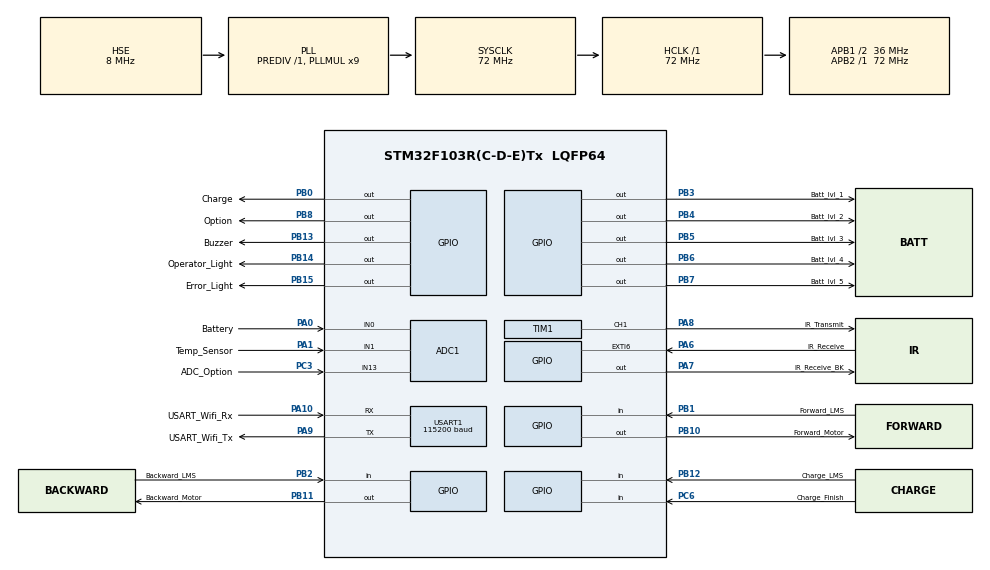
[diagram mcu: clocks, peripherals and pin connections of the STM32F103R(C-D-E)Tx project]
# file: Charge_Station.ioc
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ADC1.Channel-0\#ChannelRegularConversion=ADC_CHANNEL_0
ADC1.Channel-1\#ChannelRegularConversion=ADC_CHANNEL_1
ADC1.Channel-2\#ChannelRegularConversion=ADC_CHANNEL_13
ADC1.ContinuousConvMode=ENABLE
ADC1.DataAlign=ADC_DATAALIGN_RIGHT
ADC1.DiscontinuousConvMode=DISABLE
ADC1.EnableAnalogWatchDog=false
ADC1.EnableRegularConversion=ENABLE
ADC1.ExternalTrigConv=ADC_SOFTWARE_START
ADC1.InjNumberOfConversion=0
ADC1.NbrOfConversion=3
ADC1.NbrOfConversionFlag=1
ADC1.Rank-0\#ChannelRegularConversion=1
ADC1.Rank-1\#ChannelRegularConversion=2
ADC1.Rank-2\#ChannelRegularConversion=3
ADC1.SamplingTime-0\#ChannelRegularConversion=ADC_SAMPLETIME_239CYCLES_5
ADC1.SamplingTime-1\#ChannelRegularConversion=ADC_SAMPLETIME_239CYCLES_5
ADC1.SamplingTime-2\#ChannelRegularConversion=ADC_SAMPLETIME_239CYCLES_5
ADC1.ScanConvMode=ADC_SCAN_ENABLE
ADC1.master=1
Dma.ADC1.1.Direction=DMA_PERIPH_TO_MEMORY
Dma.ADC1.1.Instance=DMA1_Channel1
Dma.ADC1.1.MemDataAlignment=DMA_MDATAALIGN_HALFWORD
Dma.ADC1.1.MemInc=DMA_MINC_ENABLE
Dma.ADC1.1.Mode=DMA_CIRCULAR
Dma.ADC1.1.PeriphDataAlignment=DMA_PDATAALIGN_HALFWORD
Dma.ADC1.1.PeriphInc=DMA_PINC_DISABLE
Dma.ADC1.1.Priority=DMA_PRIORITY_LOW
Dma.Request0=USART1_RX
Dma.Request1=ADC1
Dma.USART1_RX.0.Direction=DMA_PERIPH_TO_MEMORY
Dma.USART1_RX.0.Instance=DMA1_Channel5
Dma.USART1_RX.0.MemDataAlignment=DMA_MDATAALIGN_BYTE
Dma.USART1_RX.0.MemInc=DMA_MINC_ENABLE
Dma.USART1_RX.0.Mode=DMA_CIRCULAR
Dma.USART1_RX.0.PeriphDataAlignment=DMA_PDATAALIGN_BYTE
Dma.USART1_RX.0.PeriphInc=DMA_PINC_DISABLE
Dma.USART1_RX.0.Priority=DMA_PRIORITY_LOW
Mcu.Family=STM32F1
Mcu.Name=STM32F103R(C-D-E)Tx
Mcu.Package=LQFP64
NVIC.ADC1_2_IRQn=true\:0\:0\:false\:false\:true\:true
NVIC.DMA1_Channel1_IRQn=true\:0\:0\:false\:false\:true\:true
NVIC.DMA1_Channel5_IRQn=true\:0\:0\:false\:false\:true\:true
NVIC.PriorityGroup=NVIC_PRIORITYGROUP_4
NVIC.TIM2_IRQn=true\:0\:0\:false\:false\:true\:true
NVIC.TIM3_IRQn=true\:0\:0\:false\:false\:true\:true
NVIC.TIM4_IRQn=true\:0\:0\:false\:false\:true\:true
NVIC.USART1_IRQn=true\:0\:0\:false\:false\:true\:true
PA0-WKUP.GPIO_Label=Battery
PA0-WKUP.Signal=ADCx_IN0
PA1.GPIO_Label=Temp_Sensor
PA1.Signal=ADCx_IN1
PA10.GPIO_Label=USART_Wifi_Rx
PA10.Mode=Asynchronous
PA10.Signal=USART1_RX
PA13.Mode=Serial_Wire
PA13.Signal=SYS_JTMS-SWDIO
PA14.Mode=Serial_Wire
PA14.Signal=SYS_JTCK-SWCLK
PA6.GPIO_Label=IR_Receive
PA6.GPIO_ModeDefaultEXTI=GPIO_MODE_IT_RISING_FALLING
PA6.Signal=GPXTI6
PA7.GPIO_Label=IR_Receive_BK
PA7.Signal=GPIO_Output
PA8.GPIO_Label=IR_Transmit
PA8.Signal=S_TIM1_CH1
PA9.GPIO_Label=USART_Wifi_Tx
PA9.Mode=Asynchronous
PA9.Signal=USART1_TX
PB0.GPIO_Label=Charge
PB0.GPIO_Speed=GPIO_SPEED_FREQ_HIGH
PB0.Signal=GPIO_Output
PB1.GPIO_Label=Forward_LMS
PB1.Signal=GPIO_Input
PB10.GPIO_Label=Forward_Motor
PB10.GPIO_Speed=GPIO_SPEED_FREQ_HIGH
PB10.Signal=GPIO_Output
PB11.GPIO_Label=Backward_Motor
PB11.GPIO_ModeDefaultOutputPP=GPIO_MODE_OUTPUT_PP
PB11.GPIO_Speed=GPIO_SPEED_FREQ_HIGH
PB11.PinState=GPIO_PIN_RESET
PB11.Signal=GPIO_Output
PB12.GPIO_Label=Charge_LMS
PB12.Signal=GPIO_Input
PB13.GPIO_Label=Buzzer
PB13.GPIO_Speed=GPIO_SPEED_FREQ_HIGH
PB13.Signal=GPIO_Output
PB14.GPIO_Label=Operator_Light
PB14.GPIO_Speed=GPIO_SPEED_FREQ_HIGH
PB14.Signal=GPIO_Output
PB15.GPIO_Label=Error_Light
PB15.GPIO_Speed=GPIO_SPEED_FREQ_HIGH
PB15.Signal=GPIO_Output
PB2.GPIO_Label=Backward_LMS
PB2.Signal=GPIO_Input
PB3.GPIO_Label=Batt_lvl_1
PB3.GPIO_ModeDefaultOutputPP=GPIO_MODE_OUTPUT_PP
PB3.GPIO_Speed=GPIO_SPEED_FREQ_HIGH
PB3.PinState=GPIO_PIN_RESET
PB3.Signal=GPIO_Output
PB4.GPIO_Label=Batt_lvl_2
PB4.GPIO_ModeDefaultOutputPP=GPIO_MODE_OUTPUT_PP
PB4.GPIO_Speed=GPIO_SPEED_FREQ_HIGH
PB4.PinState=GPIO_PIN_RESET
PB4.Signal=GPIO_Output
PB5.GPIO_Label=Batt_lvl_3
PB5.GPIO_ModeDefaultOutputPP=GPIO_MODE_OUTPUT_PP
PB5.GPIO_Speed=GPIO_SPEED_FREQ_HIGH
PB5.PinState=GPIO_PIN_RESET
PB5.Signal=GPIO_Output
PB6.GPIO_Label=Batt_lvl_4
PB6.GPIO_ModeDefaultOutputPP=GPIO_MODE_OUTPUT_PP
PB6.GPIO_Speed=GPIO_SPEED_FREQ_HIGH
PB6.PinState=GPIO_PIN_RESET
PB6.Signal=GPIO_Output
PB7.GPIO_Label=Batt_lvl_5
PB7.GPIO_ModeDefaultOutputPP=GPIO_MODE_OUTPUT_PP
PB7.GPIO_Speed=GPIO_SPEED_FREQ_HIGH
PB7.PinState=GPIO_PIN_RESET
PB7.Signal=GPIO_Output
PB8.GPIO_Label=Option
PB8.GPIO_ModeDefaultOutputPP=GPIO_MODE_OUTPUT_PP
PB8.GPIO_Speed=GPIO_SPEED_FREQ_HIGH
PB8.PinState=GPIO_PIN_RESET
PB8.Signal=GPIO_Output
PC3.GPIO_Label=ADC_Option
PC3.Signal=ADCx_IN13
PC6.GPIO_Label=Charge_Finish
PC6.Signal=GPIO_Input
PD0-OSC_IN.Mode=HSE-External-Oscillator
PD0-OSC_IN.Signal=RCC_OSC_IN
PD1-OSC_OUT.Mode=HSE-External-Oscillator
PD1-OSC_OUT.Signal=RCC_OSC_OUT
ProjectManager.HeapSize=0x200
ProjectManager.StackSize=0x400
ProjectManager.TargetToolchain=MDK-ARM V5
RCC.ADCPresc=RCC_ADCPCLK2_DIV6
RCC.AHBFreq_Value=72000000
RCC.APB1CLKDivider=RCC_HCLK_DIV2
RCC.APB1Freq_Value=36000000
RCC.APB1TimFreq_Value=72000000
RCC.APB2Freq_Value=72000000
RCC.APB2TimFreq_Value=72000000
RCC.HCLKFreq_Value=72000000
RCC.PLLMUL=RCC_PLL_MUL9
RCC.PLLSourceVirtual=RCC_PLLSOURCE_HSE
RCC.SYSCLKFreq_VALUE=72000000
RCC.SYSCLKSource=RCC_SYSCLKSOURCE_PLLCLK
RCC.USBFreq_Value=72000000
SH.ADCx_IN0.0=ADC1_IN0,IN0
SH.ADCx_IN1.0=ADC1_IN1,IN1
SH.ADCx_IN13.0=ADC1_IN13,IN13
SH.S_TIM1_CH1.0=TIM1_CH1,PWM Generation1 CH1
TIM1.Channel-PWM\ Generation1\ CH1=TIM_CHANNEL_1
TIM1.Period=1799
TIM2.Channel-Output\ Compare1\ No\ Output=TIM_CHANNEL_1
TIM2.OCMode_1=TIM_OCMODE_ACTIVE
TIM2.Period=599
TIM2.Prescaler=71
TIM3.Period=2999
TIM3.Prescaler=71
TIM4.Prescaler=71
USART1.BaudRate=115200
USART1.VirtualMode=VM_ASYNC
VP_TIM1_VS_ClockSourceINT.Mode=Internal
VP_TIM2_VS_ClockSourceINT.Mode=Internal
VP_TIM2_VS_no_output1.Mode=Output Compare1 No Output
VP_TIM3_VS_ClockSourceINT.Mode=Internal
VP_TIM4_VS_ClockSourceINT.Mode=Internal
board=Charge_Station

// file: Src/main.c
/**
  ******************************************************************************
  * File Name          : main.c
  * Description        : Main program body
  ******************************************************************************
  ** This notice applies to any and all portions of this file
  * that are not between comment pairs USER CODE BEGIN and
  * USER CODE END. Other portions of this file, whether
  * inserted by the user or by software development tools
  * are owned by their respective copyright owners.
  *
  * COPYRIGHT(c) 2018 STMicroelectronics
  *
  * Redistribution and use in source and binary forms, with or without modification,
  * are permitted provided that the following conditions are met:
  *   1. Redistributions of source code must retain the above copyright notice,
  *      this list of conditions and the following disclaimer.
  *   2. Redistributions in binary form must reproduce the above copyright notice,
  *      this list of conditions and the following disclaimer in the documentation
  *      and/or other materials provided with the distribution.
  *   3. Neither the name of STMicroelectronics nor the names of its contributors
  *      may be used to endorse or promote products derived from this software
  *      without specific prior written permission.
  *
  * THIS SOFTWARE IS PROVIDED BY THE COPYRIGHT HOLDERS AND CONTRIBUTORS "AS IS"
  * AND ANY EXPRESS OR IMPLIED WARRANTIES, INCLUDING, BUT NOT LIMITED TO, THE
  * IMPLIED WARRANTIES OF MERCHANTABILITY AND FITNESS FOR A PARTICULAR PURPOSE ARE
  * DISCLAIMED. IN NO EVENT SHALL THE COPYRIGHT HOLDER OR CONTRIBUTORS BE LIABLE
  * FOR ANY DIRECT, INDIRECT, INCIDENTAL, SPECIAL, EXEMPLARY, OR CONSEQUENTIAL
  * DAMAGES (INCLUDING, BUT NOT LIMITED TO, PROCUREMENT OF SUBSTITUTE GOODS OR
  * SERVICES; LOSS OF USE, DATA, OR PROFITS; OR BUSINESS INTERRUPTION) HOWEVER
  * CAUSED AND ON ANY THEORY OF LIABILITY, WHETHER IN CONTRACT, STRICT LIABILITY,
  * OR TORT (INCLUDING NEGLIGENCE OR OTHERWISE) ARISING IN ANY WAY OUT OF THE USE
  * OF THIS SOFTWARE, EVEN IF ADVISED OF THE POSSIBILITY OF SUCH DAMAGE.
  *
  ******************************************************************************
  */
#include "main.h"
#include "stm32f1xx_hal.h"
#include "math.h"

#define State_1  0
#define State_2  1
#define State_3	 2
#define State_4	 3

#define Not_yet   0
#define Full		 1

#define Station_ID 	  	3000
#define Waiting 				6000
#define Charge_Start 		6001
#define Charging 	    	6002
#define Reset_Workflow 	6003

#define Charge_waiting 			7000
#define Charge_motor_error 	7001
#define Charge_charging			7002
#define Charge_full					7003
#define Charge_prepare			7004
#define Charge_reset				7005
#define Charge_unknown			7006

#define Charge_Enable HAL_GPIO_WritePin(GPIOB,Charge_Pin,GPIO_PIN_SET);
#define Charge_Disable HAL_GPIO_WritePin(GPIOB,Charge_Pin,GPIO_PIN_RESET);

#define Operator_On HAL_GPIO_WritePin(GPIOB,Operator_Light_Pin,GPIO_PIN_SET);
#define Operator_Off HAL_GPIO_WritePin(GPIOB,Operator_Light_Pin,GPIO_PIN_RESET);

#define Error_On HAL_GPIO_WritePin(GPIOB,Error_Light_Pin,GPIO_PIN_SET);
#define Error_Off HAL_GPIO_WritePin(GPIOB,Error_Light_Pin,GPIO_PIN_RESET);

#define Buzzer_On HAL_GPIO_WritePin(GPIOB,Buzzer_Pin,GPIO_PIN_SET);
#define Buzzer_Off HAL_GPIO_WritePin(GPIOB,Buzzer_Pin,GPIO_PIN_RESET);

#define THERMISTORNOMINAL 10000
#define TEMPERATURENOMINAL 25
#define NUMSAMPLES 5
#define BCOEFFICIENT 3950
#define SERIESRESISTOR 10000
uint16_t samples[NUMSAMPLES];

ADC_HandleTypeDef hadc1;
DMA_HandleTypeDef hdma_adc1;

TIM_HandleTypeDef htim1;
TIM_HandleTypeDef htim2;
TIM_HandleTypeDef htim3;
TIM_HandleTypeDef htim4;

UART_HandleTypeDef huart1;
DMA_HandleTypeDef hdma_usart1_rx;

/* USER CODE BEGIN PV */
/* Private variables ---------------------------------------------------------*/

/* USER CODE END PV */

void SystemClock_Config(void);
static void MX_GPIO_Init(void);
static void MX_DMA_Init(void);
static void MX_USART1_UART_Init(void);
static void MX_TIM1_Init(void);
static void MX_TIM2_Init(void);
static void MX_TIM3_Init(void);
static void MX_TIM4_Init(void);
static void MX_ADC1_Init(void);

void HAL_TIM_MspPostInit(TIM_HandleTypeDef *htim);

void get_data(void);
void battery_indicator(void);
void error_blink(int i);
void Operator_blink();
/*------------ Timer delay -------------*/
void delay_us(uint16_t microseconds);

void Motor_Forward(void);
void Motor_Backward(void);
void Motor_Off(void);

//ADC
//================================================================================//
volatile uint16_t adc1_value[3];
int adc1_value_temp = 0;
float adc1_value_batt = 0;
float NTC_value = 0;
float min_diff = 1000;
float batt_temp ;
int count = 0;
int bat_full_flag = 0;
int flag = 0;
//-20 => 105
/*
float Temp_lookup_table[126] = {\
		 70.5811, 67.2987, 64.1834, 61.2233, 58.4080, 55.7284, 53.1766, 50.7456, 48.4294, 46.2224, 44.1201, 42.1180, 40.2121\
		,38.3988, 36.6746, 35.0362, 33.4802, 32.0035, 30.6028, 29.2750, 28.0170, 26.8255, 25.6972, 24.6290, 23.6176, 22.6597\
		,21.7522, 20.8916, 20.0749, 19.2988, 18.5600, 18.4818, 18.1489, 17.6316, 16.9917, 16.2797, 15.5350, 14.7867, 14.0551\
		,13.3536, 12.6900, 12.0684, 11.4900, 10.9539, 10.4582, 10.0000, 9.5762,  9.1835,  8.8186,  8.4784,  8.1600,  7.8608\
		,7.5785,  7.3109,  7.0564,  6.8133,  6.5806,  6.3570,  6.1418,  5.9343,  5.7340,  5.5405,  5.3534,  5.1725,  4.9976\
		,4.8286,  4.6652,  4.5073,  4.3548,  4.2075,  4.0650,	 3.9271,  3.7936,  3.6639,  3.5377,  3.4146,  3.2939,  3.1752\
	  ,3.0579,  2.9414,  2.8250,  2.7762,  2.7179,  2.6523,  2.5817,  2.5076,  2.4319,  2.3557,  2.2803,  2.2065,  2.1350\
    ,2.0661,  2.0004,  1.9378,  1.8785,  1.8225,  1.7696,  1.7197,  1.6727,  1.6282,  1.5860,  1.5458,  1.5075,  1.4707\
	  ,1.4352,  1.4006,  1.3669,  1.3337,  1.3009,  1.2684,  1.2360,  1.2037,  1.1714,  1.1390,  1.1067,  1.0744,  1.0422\
    ,1.0104,  0.9789,  0.9481,  0.9180,  0.8889,  0.85,    0.8346,  0.8099,  0.7870};
*/
//UART WIFI
//================================================================================//
uint8_t buffer[100],receive_data[6];
uint8_t data_complete = 0, data_len = 0;
uint16_t data_id = 0;
uint8_t len = 0;
uint8_t data_order = 0, data_order_2 = 0;
uint8_t data_reorder[6];

//WORKFLOW
//================================================================================//
uint8_t workflow = 0, lms_ = 1, wait_motor = 0, charge_complete = 0;

double temp_calculate(int adc)
{

    double Temp;

    double ara;        //(10000*((4096/(adc-1))));

    ara=adc-1;

    ara=4096/ara;

    ara=ara*10000;

    Temp = log(ara);
   //         =log(10000/(4095/adc-1)) // for pull-up configuration

    Temp=pow(Temp,2);

    Temp=Temp*0.0000000876741;

    Temp=Temp+0.000234125;

    Temp=Temp*(log(ara));

    Temp=Temp+0.001129148;

    Temp=(1/Temp);

    //Temp = log(10000.0*((1024.0/RawADC-1)))
    //Temp = 1 / (0.001129148 + (0.000234125 + (0.0000000876741 * Temp * Temp ))* Temp )

    Temp = Temp - 273.15;            // Convert Kelvin to Celcius

    // Temp = (Temp * 9.0)/ 5.0 + 32.0; // Convert Celcius to Fahrenheit

    return Temp;

}

int main(void)
{
  /* MCU Configuration----------------------------------------------------------*/

  /* Reset of all peripherals, Initializes the Flash interface and the Systick. */
  HAL_Init();

  /* Configure the system clock */
  SystemClock_Config();

  /* Initialize all configured peripherals */
  MX_GPIO_Init();
  MX_DMA_Init();
  MX_USART1_UART_Init();
  MX_TIM1_Init();
  MX_TIM2_Init();
  MX_TIM3_Init();
  MX_TIM4_Init();
  MX_ADC1_Init();

	HAL_TIM_Base_Start(&htim4);
  HAL_TIM_Base_Start_IT(&htim3);
	//---Battery LED---
	HAL_GPIO_WritePin(GPIOB,Batt_lvl_1_Pin,GPIO_PIN_SET	);
	HAL_GPIO_WritePin(GPIOB,Batt_lvl_2_Pin,GPIO_PIN_SET);
	HAL_GPIO_WritePin(GPIOB,Batt_lvl_3_Pin,GPIO_PIN_SET);
	HAL_GPIO_WritePin(GPIOB,Batt_lvl_4_Pin,GPIO_PIN_SET);
	HAL_GPIO_WritePin(GPIOB,Batt_lvl_5_Pin,GPIO_PIN_SET);

	//---Error Light---//0 = off
	Error_Off;
	//---Operator Light---//0 = off
	Operator_Off;
	//---Buzzer---//0 = off
	Buzzer_Off;

	//---Charge---//0 = off
	Charge_Disable;
	//---Motor---//0 = off
	Motor_Off();

	//---UART DMA---
	len = sizeof(receive_data)/sizeof(receive_data[0]);
	HAL_UART_Receive_DMA(&huart1,receive_data,len);

	//---ADC DMA---
	HAL_ADC_Start_DMA(&hadc1,(uint32_t*) adc1_value,3);
	HAL_Delay(1000);

  /* USER CODE BEGIN WHILE */
  while (1)
  {
		//Get DMA data
		get_data();

		//Auto restart if temp too high
		if (adc1_value_temp >= 90){
						snprintf((char*)buffer, sizeof buffer\
						,"%s%d%s%d%s%d%s%.1f%s"\
						,"{\"id\":",Station_ID,",\"status\":",Charge_reset,",\"temp\":",adc1_value_temp,",\"batt\":",adc1_value_batt,"}\n");//r
						HAL_UART_Transmit_IT(&huart1,buffer, sizeof buffer);
						Charge_Disable;
						Motor_Backward();
						while(wait_motor <= 100){
							delay_us(50000);
							wait_motor++;
						}
						for (int i=0; i<len; i++) receive_data[i] = '\0';
						data_complete = 0;
						workflow = State_1;
						Error_On;
						Operator_Off;
		}
		if (adc1_value_batt <=2){
			count +=1;
			if (count >= 50){
						snprintf((char*)buffer, sizeof buffer\
				,"%s%d%s%d%s%d%s%.1f%s"\
				,"{\"id\":",Station_ID,",\"status\":",Charge_reset,",\"temp\":",adc1_value_temp,",\"batt\":",adc1_value_batt,"}\n");//r
			HAL_UART_Transmit_IT(&huart1,buffer, sizeof buffer);
			Charge_Disable;
			Motor_Backward();
			while(wait_motor <= 100){
				delay_us(50000);
				wait_motor++;
			}
			for (int i=0; i<len; i++) receive_data[i] = '\0';
			data_complete = 0;
			workflow = State_1;
			Error_Off;
			Operator_Off;
			count = 0;
		}
	}
		//Response to server while waiting
		if ((data_complete == 1)&&(data_id == Waiting)&&(workflow == State_1)){
			snprintf((char*)buffer, sizeof buffer\
				,"%s%d%s%d%s%d%s%.1f%s"\
				,"{\"id\":",Station_ID,",\"status\":",Charge_waiting,",\"temp\":",adc1_value_temp,",\"batt\":",adc1_value_batt,"}\n");//r
			HAL_UART_Transmit_IT(&huart1,buffer, sizeof buffer);
			for (int i=0; i<len; i++) receive_data[i] = '\0';
			data_complete = 0;
			//charge_complete = 0;
			Error_Off;
			Operator_Off;
			count = 0;
		}
		//Response to server while starting to charge
		else if ((data_complete == 1)&&(data_id == Charge_Start)&&(workflow == State_1)){
			Motor_Forward();
			//HAL_Delay(500);
			snprintf((char*)buffer, sizeof buffer\
				,"%s%d%s%d%s%d%s%.1f%s"\
				,"{\"id\":",Station_ID,",\"status\":",Charge_prepare,",\"temp\":",adc1_value_temp,",\"batt\":",adc1_value_batt,"}\n");//r
			HAL_UART_Transmit_IT(&huart1,buffer, sizeof buffer);
			wait_motor = 0;
			while(wait_motor <= 100){
				delay_us(50000);
				wait_motor++;
				Error_Off;
				Operator_On;
			}

			if (HAL_GPIO_ReadPin(GPIOB,Charge_LMS_Pin) == 1 ){
				lms_ = 1;
				workflow = State_3;
				Error_On;
				Operator_Off;
				count = 0;
			}
			else if (HAL_GPIO_ReadPin(GPIOB,Charge_LMS_Pin) == 0){
				int temp_wait = 0;
				while(wait_motor <= 60){
				delay_us(50000);
				temp_wait++;
				}
				if (adc1_value_batt <=2){
					lms_ = 1;
					Operator_Off;
					//Error_On;
					error_blink(10);
					workflow = State_4;
					count = 0;
					/*
					Motor_Backward();
					wait_motor = 0;
					while(wait_motor <= 100){
						delay_us(50000);
						wait_motor++;
					}
					*/

				}
				else{
					lms_ = 0;
					workflow = State_2;
					Charge_Enable;
					Error_Off;
					Operator_On;
					count = 0;
				}
			}

			Motor_Off();
			data_complete = 0;
			for (int i=0; i<len; i++) receive_data[i] = '\0';
		}
		//Response to server while motor error
		else if ((data_complete == 1)&&(data_id == Charging)&&(workflow == State_3)){
			snprintf((char*)buffer, sizeof buffer\
				,"%s%d%s%d%s%d%s%.1f%s"\
				,"{\"id\":",Station_ID,",\"status\":",Charge_motor_error,",\"temp\":",adc1_value_temp,",\"batt\":",adc1_value_batt,"}\n");//r
			HAL_UART_Transmit_IT(&huart1,buffer, sizeof buffer);
			for (int i=0; i<len; i++) receive_data[i] = '\0';
			data_complete = 0;
			data_id = Reset_Workflow;
		}
		// error when no robot to charge
		else if (workflow == State_4){
			Charge_Disable;
			Motor_Backward();
			while(wait_motor <= 100){
				delay_us(50000);
				wait_motor++;
			}
			data_complete = 0;
			workflow = State_1;
			Error_Off;
			Operator_Off;
		}
		//Response to server while charging
		else if ((data_complete == 1)&&(data_id == Charging)&&(workflow == State_2)){
			flag = 0;
			if ((adc1_value_batt < 29.0)&&(flag == 0)){
				snprintf((char*)buffer, sizeof buffer\
				,"%s%d%s%d%s%d%s%.1f%s"\
				,"{\"id\":",Station_ID,",\"status\":",Charge_charging,",\"temp\":",adc1_value_temp,",\"batt\":",adc1_value_batt,"}\n");//r

			HAL_UART_Transmit_IT(&huart1,buffer, sizeof buffer);
			for (int i=0; i<len; i++) receive_data[i] = '\0';
			data_complete = 0;
			bat_full_flag = 0;
			flag = 1;
		}
			else{
				snprintf((char*)buffer, sizeof buffer\
				,"%s%d%s%d%s%d%s%.1f%s"\
				,"{\"id\":",Station_ID,",\"status\":",Charge_charging,",\"temp\":",adc1_value_temp,",\"batt\":",adc1_value_batt,"}\n");//r

			HAL_UART_Transmit_IT(&huart1,buffer, sizeof buffer);
			for (int i=0; i<len; i++) receive_data[i] = '\0';
			data_complete = 0;
			bat_full_flag +=1;
			flag = 1;
			}
		}
		//Reset charge station workflow
		else if ((data_complete == 1)&&(data_id == Reset_Workflow)){
			snprintf((char*)buffer, sizeof buffer\
				,"%s%d%s%d%s%d%s%.1f%s"\
				,"{\"id\":",Station_ID,",\"status\":",Charge_reset,",\"temp\":",adc1_value_temp,",\"batt\":",adc1_value_batt,"}\n");//r
			HAL_UART_Transmit_IT(&huart1,buffer, sizeof buffer);
			Charge_Disable;
			Motor_Backward();
			while(wait_motor <= 100){
				delay_us(50000);
				wait_motor++;
			}
			for (int i=0; i<len; i++) receive_data[i] = '\0';
			data_complete = 0;
			workflow = State_1;
			Error_Off;
			Operator_Off;
		}

		else if ((data_complete == 1)&&(data_id != Reset_Workflow)) {
			snprintf((char*)buffer, sizeof buffer\

				,"%s%d%s%d%s%d%s%.1f%s"\

				,"{\"id\":",Station_ID,",\"status\":",Charge_unknown,",\"temp\":",adc1_value_temp,",\"batt\":",adc1_value_batt,"}\n");//r

			HAL_UART_Transmit_IT(&huart1,buffer, sizeof buffer);

			for (int i=0; i<len; i++) receive_data[i] = '\0';

			data_complete = 0;

		}

		//Full condition
		if ((workflow == State_2)&&(bat_full_flag >= 6)){
			Charge_Disable;
			snprintf((char*)buffer, sizeof buffer\
				,"%s%d%s%d%s%d%s%.1f%s"\
				,"{\"id\":",Station_ID,",\"status\":",Charge_full,",\"temp\":",adc1_value_temp,",\"batt\":",adc1_value_batt,"}\n");//r
			HAL_UART_Transmit_IT(&huart1,buffer, sizeof buffer);
			for (int i=0; i<len; i++) receive_data[i] = '\0';
			data_complete = 0;

			delay_us(5000);
			Motor_Backward();
			wait_motor = 0;
			while(wait_motor <= 100){
				delay_us(50000);
				wait_motor++;
			}
			Error_Off;
			Operator_On;
			count = 0;
			bat_full_flag = 0;
	}

		//while charging show battery lvl
		if (workflow == State_2)
			battery_indicator();
		else if(workflow != State_2){
			if(workflow == State_1){
				Operator_blink();
			}
				HAL_GPIO_WritePin(GPIOB,Batt_lvl_1_Pin,GPIO_PIN_SET);
				HAL_GPIO_WritePin(GPIOB,Batt_lvl_2_Pin,GPIO_PIN_SET);
				HAL_GPIO_WritePin(GPIOB,Batt_lvl_3_Pin,GPIO_PIN_SET);
				HAL_GPIO_WritePin(GPIOB,Batt_lvl_4_Pin,GPIO_PIN_SET);
				HAL_GPIO_WritePin(GPIOB,Batt_lvl_5_Pin,GPIO_PIN_SET);
		}
  }
}

/** System Clock Configuration
*/
void HAL_TIM_PeriodElapsedCallback(TIM_HandleTypeDef *htim)
{
	if (htim->Instance==htim3.Instance)
	{
		//Battery calc
		//adc1_value_batt = adc1_value[0]*0.00764432f;
		float adc1_batt_total = 0;
		for (int i = 0;i<16;i++)
		{
			 adc1_batt_total += adc1_value[0];
			 delay_us(100);
		}
		batt_temp += ((adc1_batt_total/16) - batt_temp)*0.1;
		adc1_value_batt = batt_temp*0.007645756633f;//charge_1:ID:1000:0.00764432f//charge_2:ID:2000:0.0076330722787276f//charge_3:ID:3000:0.007645756633f
		//Temp of charge station
		/*
		NTC_value = (10.89 * adc1_value[1])/(13513.5 - (3.3 * adc1_value[1]));
		min_diff = 1000;
		for (int i = 0; i<126; i++){
			if (fabs(Temp_lookup_table[i] - NTC_value) <= min_diff){
				min_diff = fabs(Temp_lookup_table[i] - NTC_value);
				adc1_value_temp = i - 20;
			}
		}

		uint8_t i;
		float average;

		// take N samples in a row, with a slight delay
		for (i=0; i< NUMSAMPLES; i++) {
		samples[i] = adc1_value[1];
		}

		// average all the samples out
		average = 0;
		for (i=0; i< NUMSAMPLES; i++) {
			average += samples[i];
		}
		average /= NUMSAMPLES;

		// convert the value to resistance
		average = 4095 / average - 1;
		average = SERIESRESISTOR / average;

		float steinhart;
		steinhart = average / THERMISTORNOMINAL;     // (R/Ro)
		steinhart = log(steinhart);                  // ln(R/Ro)
		steinhart /= BCOEFFICIENT;                   // 1/B * ln(R/Ro)
		steinhart += 1.0 / (TEMPERATURENOMINAL + 273.15); // + (1/To)
		steinhart = 1.0 / steinhart;                 // Invert
		steinhart -= 273.15;
		adc1_value_temp = steinhart;
		*/
		adc1_value_temp = temp_calculate(adc1_value[1]);
	}
}

void error_blink(int i){
	for(int a = 0; a<i;a++)
	{
	HAL_GPIO_TogglePin(GPIOB,Error_Light_Pin);
	HAL_Delay(500);
	}
}
void Operator_blink(){
	HAL_GPIO_TogglePin(GPIOB,Operator_Light_Pin);
	HAL_Delay(500);
}
void battery_indicator(void){
	//adc1_value_batt = adc1_value[0]*0.007531f;

	if (adc1_value_batt < 26){
		HAL_GPIO_WritePin(GPIOB,Batt_lvl_1_Pin,GPIO_PIN_RESET);
		HAL_GPIO_WritePin(GPIOB,Batt_lvl_2_Pin,GPIO_PIN_SET);
		HAL_GPIO_WritePin(GPIOB,Batt_lvl_3_Pin,GPIO_PIN_SET);
		HAL_GPIO_WritePin(GPIOB,Batt_lvl_4_Pin,GPIO_PIN_SET);
		HAL_GPIO_WritePin(GPIOB,Batt_lvl_5_Pin,GPIO_PIN_SET);
	}
	else if (adc1_value_batt < 27){
		HAL_GPIO_WritePin(GPIOB,Batt_lvl_1_Pin,GPIO_PIN_RESET);
		HAL_GPIO_WritePin(GPIOB,Batt_lvl_2_Pin,GPIO_PIN_RESET);
		HAL_GPIO_WritePin(GPIOB,Batt_lvl_3_Pin,GPIO_PIN_SET);
		HAL_GPIO_WritePin(GPIOB,Batt_lvl_4_Pin,GPIO_PIN_SET);
		HAL_GPIO_WritePin(GPIOB,Batt_lvl_5_Pin,GPIO_PIN_SET);
	}
	else if (adc1_value_batt < 28){
		HAL_GPIO_WritePin(GPIOB,Batt_lvl_1_Pin,GPIO_PIN_RESET);
		HAL_GPIO_WritePin(GPIOB,Batt_lvl_2_Pin,GPIO_PIN_RESET);
		HAL_GPIO_WritePin(GPIOB,Batt_lvl_3_Pin,GPIO_PIN_RESET);
		HAL_GPIO_WritePin(GPIOB,Batt_lvl_4_Pin,GPIO_PIN_SET);
		HAL_GPIO_WritePin(GPIOB,Batt_lvl_5_Pin,GPIO_PIN_SET);
	}
	else if (adc1_value_batt < 29){
		HAL_GPIO_WritePin(GPIOB,Batt_lvl_1_Pin,GPIO_PIN_RESET);
		HAL_GPIO_WritePin(GPIOB,Batt_lvl_2_Pin,GPIO_PIN_RESET);
		HAL_GPIO_WritePin(GPIOB,Batt_lvl_3_Pin,GPIO_PIN_RESET);
		HAL_GPIO_WritePin(GPIOB,Batt_lvl_4_Pin,GPIO_PIN_RESET);
		HAL_GPIO_WritePin(GPIOB,Batt_lvl_5_Pin,GPIO_PIN_SET);
	}
	else if (adc1_value_batt >= 29.3){
		HAL_GPIO_WritePin(GPIOB,Batt_lvl_1_Pin,GPIO_PIN_RESET);
		HAL_GPIO_WritePin(GPIOB,Batt_lvl_2_Pin,GPIO_PIN_RESET);
		HAL_GPIO_WritePin(GPIOB,Batt_lvl_3_Pin,GPIO_PIN_RESET);
		HAL_GPIO_WritePin(GPIOB,Batt_lvl_4_Pin,GPIO_PIN_RESET);
		HAL_GPIO_WritePin(GPIOB,Batt_lvl_5_Pin,GPIO_PIN_RESET);
	}
}

void Motor_Forward(void){
	HAL_GPIO_WritePin(GPIOB,Forward_Motor_Pin,GPIO_PIN_SET);
	HAL_GPIO_WritePin(GPIOB,Backward_Motor_Pin,GPIO_PIN_RESET);
}

void Motor_Backward(void){
	HAL_GPIO_WritePin(GPIOB,Forward_Motor_Pin,GPIO_PIN_RESET);
	HAL_GPIO_WritePin(GPIOB,Backward_Motor_Pin,GPIO_PIN_SET);
}

void Motor_Off(void){
	HAL_GPIO_WritePin(GPIOB,Forward_Motor_Pin,GPIO_PIN_RESET);
	HAL_GPIO_WritePin(GPIOB,Backward_Motor_Pin,GPIO_PIN_RESET);
}

void get_data(void)
{
		//find the order of data
		for (int i = 0; i<len; i++){
			if (receive_data[i] == 'c')
				data_order = i;
		}

		if (data_order != 0){
			for (int i = 0; i<len; i++){
				data_reorder[i] = receive_data[data_order];
				data_order_2 = i+1;
				data_order++;
				if (data_order == len)
					break;
			}
			for (int i = 0; i<len; i++){
				data_reorder[data_order_2] = receive_data[i];
				data_order_2++;
				if (data_order_2 == len)
					break;
			}
		}
		else{
			for (int i = 0; i<len; i++){
				data_reorder[i] = receive_data[i];
			}
		}

		//find the start and stop
		if ((data_reorder[0] == 'c')&&(data_reorder[5] == 'e')){
			data_complete = 1;
			uint16_t dec = 1000;
			data_id = 0;
			for (int i = 1; i<len; i++){
				if (data_reorder[i] == 'e') break;
				data_id = data_id + ((data_reorder[i] - '0')*dec);
				dec = dec/10;
			}
		}
}

/*--------------- Delay US ------------------*/
void delay_us(uint16_t microseconds)
{
	TIM4->CNT = 0;
	//volatile uint16_t start = TIM1->CNT;
	while((TIM4->CNT) < microseconds);
}

void SystemClock_Config(void)
{

  RCC_OscInitTypeDef RCC_OscInitStruct;
  RCC_ClkInitTypeDef RCC_ClkInitStruct;
  RCC_PeriphCLKInitTypeDef PeriphClkInit;

    /**Initializes the CPU, AHB and APB busses clocks
    */
  RCC_OscInitStruct.OscillatorType = RCC_OSCILLATORTYPE_HSE;
  RCC_OscInitStruct.HSEState = RCC_HSE_ON;
  RCC_OscInitStruct.HSEPredivValue = RCC_HSE_PREDIV_DIV1;
  RCC_OscInitStruct.HSIState = RCC_HSI_ON;
  RCC_OscInitStruct.PLL.PLLState = RCC_PLL_ON;
  RCC_OscInitStruct.PLL.PLLSource = RCC_PLLSOURCE_HSE;
  RCC_OscInitStruct.PLL.PLLMUL = RCC_PLL_MUL9;
  if (HAL_RCC_OscConfig(&RCC_OscInitStruct) != HAL_OK)
  {
    _Error_Handler(__FILE__, __LINE__);
  }

    /**Initializes the CPU, AHB and APB busses clocks
    */
  RCC_ClkInitStruct.ClockType = RCC_CLOCKTYPE_HCLK|RCC_CLOCKTYPE_SYSCLK
                              |RCC_CLOCKTYPE_PCLK1|RCC_CLOCKTYPE_PCLK2;
  RCC_ClkInitStruct.SYSCLKSource = RCC_SYSCLKSOURCE_PLLCLK;
  RCC_ClkInitStruct.AHBCLKDivider = RCC_SYSCLK_DIV1;
  RCC_ClkInitStruct.APB1CLKDivider = RCC_HCLK_DIV2;
  RCC_ClkInitStruct.APB2CLKDivider = RCC_HCLK_DIV1;

  if (HAL_RCC_ClockConfig(&RCC_ClkInitStruct, FLASH_LATENCY_2) != HAL_OK)
  {
    _Error_Handler(__FILE__, __LINE__);
  }

  PeriphClkInit.PeriphClockSelection = RCC_PERIPHCLK_ADC;
  PeriphClkInit.AdcClockSelection = RCC_ADCPCLK2_DIV6;
  if (HAL_RCCEx_PeriphCLKConfig(&PeriphClkInit) != HAL_OK)
  {
    _Error_Handler(__FILE__, __LINE__);
  }

    /**Configure the Systick interrupt time
    */
  HAL_SYSTICK_Config(HAL_RCC_GetHCLKFreq()/1000);

    /**Configure the Systick
    */
  HAL_SYSTICK_CLKSourceConfig(SYSTICK_CLKSOURCE_HCLK);

  /* SysTick_IRQn interrupt configuration */
  HAL_NVIC_SetPriority(SysTick_IRQn, 0, 0);
}

/* ADC1 init function */
static void MX_ADC1_Init(void)
{

  ADC_ChannelConfTypeDef sConfig;

    /**Common config
    */
  hadc1.Instance = ADC1;
  hadc1.Init.ScanConvMode = ADC_SCAN_ENABLE;
  hadc1.Init.ContinuousConvMode = ENABLE;
  hadc1.Init.DiscontinuousConvMode = DISABLE;
  hadc1.Init.ExternalTrigConv = ADC_SOFTWARE_START;
  hadc1.Init.DataAlign = ADC_DATAALIGN_RIGHT;
  hadc1.Init.NbrOfConversion = 3;
  if (HAL_ADC_Init(&hadc1) != HAL_OK)
  {
    _Error_Handler(__FILE__, __LINE__);
  }

    /**Configure Regular Channel
    */
  sConfig.Channel = ADC_CHANNEL_0;
  sConfig.Rank = 1;
  sConfig.SamplingTime = ADC_SAMPLETIME_239CYCLES_5;
  if (HAL_ADC_ConfigChannel(&hadc1, &sConfig) != HAL_OK)
  {
    _Error_Handler(__FILE__, __LINE__);
  }

    /**Configure Regular Channel
    */
  sConfig.Channel = ADC_CHANNEL_1;
  sConfig.Rank = 2;
  if (HAL_ADC_ConfigChannel(&hadc1, &sConfig) != HAL_OK)
  {
    _Error_Handler(__FILE__, __LINE__);
  }

    /**Configure Regular Channel
    */
  sConfig.Channel = ADC_CHANNEL_13;
  sConfig.Rank = 3;
  if (HAL_ADC_ConfigChannel(&hadc1, &sConfig) != HAL_OK)
  {
    _Error_Handler(__FILE__, __LINE__);
  }

}

/* TIM1 init function */
static void MX_TIM1_Init(void)
{

  TIM_ClockConfigTypeDef sClockSourceConfig;
  TIM_MasterConfigTypeDef sMasterConfig;
  TIM_OC_InitTypeDef sConfigOC;
  TIM_BreakDeadTimeConfigTypeDef sBreakDeadTimeConfig;

  htim1.Instance = TIM1;
  htim1.Init.Prescaler = 0;
  htim1.Init.CounterMode = TIM_COUNTERMODE_UP;
  htim1.Init.Period = 1799;
  htim1.Init.ClockDivision = TIM_CLOCKDIVISION_DIV1;
  htim1.Init.RepetitionCounter = 0;
  htim1.Init.AutoReloadPreload = TIM_AUTORELOAD_PRELOAD_DISABLE;
  if (HAL_TIM_Base_Init(&htim1) != HAL_OK)
  {
    _Error_Handler(__FILE__, __LINE__);
  }

  sClockSourceConfig.ClockSource = TIM_CLOCKSOURCE_INTERNAL;
  if (HAL_TIM_ConfigClockSource(&htim1, &sClockSourceConfig) != HAL_OK)
  {
    _Error_Handler(__FILE__, __LINE__);
  }

  if (HAL_TIM_PWM_Init(&htim1) != HAL_OK)
  {
    _Error_Handler(__FILE__, __LINE__);
  }

  sMasterConfig.MasterOutputTrigger = TIM_TRGO_RESET;
  sMasterConfig.MasterSlaveMode = TIM_MASTERSLAVEMODE_DISABLE;
  if (HAL_TIMEx_MasterConfigSynchronization(&htim1, &sMasterConfig) != HAL_OK)
  {
    _Error_Handler(__FILE__, __LINE__);
  }

  sConfigOC.OCMode = TIM_OCMODE_PWM1;
  sConfigOC.Pulse = 0;
  sConfigOC.OCPolarity = TIM_OCPOLARITY_HIGH;
  sConfigOC.OCNPolarity = TIM_OCNPOLARITY_HIGH;
  sConfigOC.OCFastMode = TIM_OCFAST_DISABLE;
  sConfigOC.OCIdleState = TIM_OCIDLESTATE_RESET;
  sConfigOC.OCNIdleState = TIM_OCNIDLESTATE_RESET;
  if (HAL_TIM_PWM_ConfigChannel(&htim1, &sConfigOC, TIM_CHANNEL_1) != HAL_OK)
  {
    _Error_Handler(__FILE__, __LINE__);
  }

  sBreakDeadTimeConfig.OffStateRunMode = TIM_OSSR_DISABLE;
  sBreakDeadTimeConfig.OffStateIDLEMode = TIM_OSSI_DISABLE;
  sBreakDeadTimeConfig.LockLevel = TIM_LOCKLEVEL_OFF;
  sBreakDeadTimeConfig.DeadTime = 0;
  sBreakDeadTimeConfig.BreakState = TIM_BREAK_DISABLE;
  sBreakDeadTimeConfig.BreakPolarity = TIM_BREAKPOLARITY_HIGH;
  sBreakDeadTimeConfig.AutomaticOutput = TIM_AUTOMATICOUTPUT_DISABLE;
  if (HAL_TIMEx_ConfigBreakDeadTime(&htim1, &sBreakDeadTimeConfig) != HAL_OK)
  {
    _Error_Handler(__FILE__, __LINE__);
  }

  HAL_TIM_MspPostInit(&htim1);

}

/* TIM2 init function */
static void MX_TIM2_Init(void)
{

  TIM_ClockConfigTypeDef sClockSourceConfig;
  TIM_MasterConfigTypeDef sMasterConfig;
  TIM_OC_InitTypeDef sConfigOC;

  htim2.Instance = TIM2;
  htim2.Init.Prescaler = 71;
  htim2.Init.CounterMode = TIM_COUNTERMODE_UP;
  htim2.Init.Period = 599;
  htim2.Init.ClockDivision = TIM_CLOCKDIVISION_DIV1;
  htim2.Init.AutoReloadPreload = TIM_AUTORELOAD_PRELOAD_DISABLE;
  if (HAL_TIM_Base_Init(&htim2) != HAL_OK)
  {
    _Error_Handler(__FILE__, __LINE__);
  }

  sClockSourceConfig.ClockSource = TIM_CLOCKSOURCE_INTERNAL;
  if (HAL_TIM_ConfigClockSource(&htim2, &sClockSourceConfig) != HAL_OK)
  {
    _Error_Handler(__FILE__, __LINE__);
  }

  if (HAL_TIM_OC_Init(&htim2) != HAL_OK)
  {
    _Error_Handler(__FILE__, __LINE__);
  }

  sMasterConfig.MasterOutputTrigger = TIM_TRGO_RESET;
  sMasterConfig.MasterSlaveMode = TIM_MASTERSLAVEMODE_DISABLE;
  if (HAL_TIMEx_MasterConfigSynchronization(&htim2, &sMasterConfig) != HAL_OK)
  {
    _Error_Handler(__FILE__, __LINE__);
  }

  sConfigOC.OCMode = TIM_OCMODE_ACTIVE;
  sConfigOC.Pulse = 0;
  sConfigOC.OCPolarity = TIM_OCPOLARITY_HIGH;
  sConfigOC.OCFastMode = TIM_OCFAST_DISABLE;
  if (HAL_TIM_OC_ConfigChannel(&htim2, &sConfigOC, TIM_CHANNEL_1) != HAL_OK)
  {
    _Error_Handler(__FILE__, __LINE__);
  }

}

/* TIM3 init function */
static void MX_TIM3_Init(void)
{

  TIM_ClockConfigTypeDef sClockSourceConfig;
  TIM_MasterConfigTypeDef sMasterConfig;

  htim3.Instance = TIM3;
  htim3.Init.Prescaler = 7199;
  htim3.Init.CounterMode = TIM_COUNTERMODE_UP;
  htim3.Init.Period = 9999;
  htim3.Init.ClockDivision = TIM_CLOCKDIVISION_DIV1;
  htim3.Init.AutoReloadPreload = TIM_AUTORELOAD_PRELOAD_DISABLE;
  if (HAL_TIM_Base_Init(&htim3) != HAL_OK)
  {
    _Error_Handler(__FILE__, __LINE__);
  }

  sClockSourceConfig.ClockSource = TIM_CLOCKSOURCE_INTERNAL;
  if (HAL_TIM_ConfigClockSource(&htim3, &sClockSourceConfig) != HAL_OK)
  {
    _Error_Handler(__FILE__, __LINE__);
  }

  sMasterConfig.MasterOutputTrigger = TIM_TRGO_RESET;
  sMasterConfig.MasterSlaveMode = TIM_MASTERSLAVEMODE_DISABLE;
  if (HAL_TIMEx_MasterConfigSynchronization(&htim3, &sMasterConfig) != HAL_OK)
  {
    _Error_Handler(__FILE__, __LINE__);
  }

}

/* TIM4 init function */
static void MX_TIM4_Init(void)
{

  TIM_ClockConfigTypeDef sClockSourceConfig;
  TIM_MasterConfigTypeDef sMasterConfig;

  htim4.Instance = TIM4;
  htim4.Init.Prescaler = 71;
  htim4.Init.CounterMode = TIM_COUNTERMODE_UP;
  htim4.Init.Period = 59999;
  htim4.Init.ClockDivision = TIM_CLOCKDIVISION_DIV1;
  htim4.Init.AutoReloadPreload = TIM_AUTORELOAD_PRELOAD_DISABLE;
  if (HAL_TIM_Base_Init(&htim4) != HAL_OK)
  {
    _Error_Handler(__FILE__, __LINE__);
  }

  sClockSourceConfig.ClockSource = TIM_CLOCKSOURCE_INTERNAL;
  if (HAL_TIM_ConfigClockSource(&htim4, &sClockSourceConfig) != HAL_OK)
  {
    _Error_Handler(__FILE__, __LINE__);
  }

  sMasterConfig.MasterOutputTrigger = TIM_TRGO_RESET;
  sMasterConfig.MasterSlaveMode = TIM_MASTERSLAVEMODE_DISABLE;
  if (HAL_TIMEx_MasterConfigSynchronization(&htim4, &sMasterConfig) != HAL_OK)
  {
    _Error_Handler(__FILE__, __LINE__);
  }

}

/* USART1 init function */
static void MX_USART1_UART_Init(void)
{

  huart1.Instance = USART1;
  huart1.Init.BaudRate = 115200;
  huart1.Init.WordLength = UART_WORDLENGTH_8B;
  huart1.Init.StopBits = UART_STOPBITS_1;
  huart1.Init.Parity = UART_PARITY_NONE;
  huart1.Init.Mode = UART_MODE_TX_RX;
  huart1.Init.HwFlowCtl = UART_HWCONTROL_NONE;
  huart1.Init.OverSampling = UART_OVERSAMPLING_16;
  if (HAL_UART_Init(&huart1) != HAL_OK)
  {
    _Error_Handler(__FILE__, __LINE__);
  }

}

static void MX_DMA_Init(void)
{
  /* DMA controller clock enable */
  __HAL_RCC_DMA1_CLK_ENABLE();

  /* DMA interrupt init */
  /* DMA1_Channel1_IRQn interrupt configuration */
  HAL_NVIC_SetPriority(DMA1_Channel1_IRQn, 0, 0);
  HAL_NVIC_EnableIRQ(DMA1_Channel1_IRQn);
  /* DMA1_Channel5_IRQn interrupt configuration */
  HAL_NVIC_SetPriority(DMA1_Channel5_IRQn, 0, 0);
  HAL_NVIC_EnableIRQ(DMA1_Channel5_IRQn);

}

/** Configure pins as
        * Analog
        * Input
        * Output
        * EVENT_OUT
        * EXTI
*/
static void MX_GPIO_Init(void)
{

  GPIO_InitTypeDef GPIO_InitStruct;

  /* GPIO Ports Clock Enable */
  __HAL_RCC_GPIOD_CLK_ENABLE();
  __HAL_RCC_GPIOC_CLK_ENABLE();
  __HAL_RCC_GPIOA_CLK_ENABLE();
  __HAL_RCC_GPIOB_CLK_ENABLE();

  /*Configure GPIO pin Output Level */
  HAL_GPIO_WritePin(IR_Receive_BK_GPIO_Port, IR_Receive_BK_Pin, GPIO_PIN_RESET);

  /*Configure GPIO pin Output Level */
  HAL_GPIO_WritePin(GPIOB, Charge_Pin|Forward_Motor_Pin|Backward_Motor_Pin|Buzzer_Pin
                          |Operator_Light_Pin|Error_Light_Pin|Batt_lvl_1_Pin|Batt_lvl_2_Pin
                          |Batt_lvl_3_Pin|Batt_lvl_4_Pin|Batt_lvl_5_Pin|Option_Pin, GPIO_PIN_RESET);

  /*Configure GPIO pin : IR_Receive_Pin */
  GPIO_InitStruct.Pin = IR_Receive_Pin;
  GPIO_InitStruct.Mode = GPIO_MODE_IT_RISING_FALLING;
  GPIO_InitStruct.Pull = GPIO_NOPULL;
  HAL_GPIO_Init(IR_Receive_GPIO_Port, &GPIO_InitStruct);

  /*Configure GPIO pin : IR_Receive_BK_Pin */
  GPIO_InitStruct.Pin = IR_Receive_BK_Pin;
  GPIO_InitStruct.Mode = GPIO_MODE_OUTPUT_PP;
  GPIO_InitStruct.Speed = GPIO_SPEED_FREQ_LOW;
  HAL_GPIO_Init(IR_Receive_BK_GPIO_Port, &GPIO_InitStruct);

  /*Configure GPIO pins : Charge_Pin Forward_Motor_Pin Backward_Motor_Pin Buzzer_Pin
                           Operator_Light_Pin Error_Light_Pin Batt_lvl_1_Pin Batt_lvl_2_Pin
                           Batt_lvl_3_Pin Batt_lvl_4_Pin Batt_lvl_5_Pin Option_Pin */
  GPIO_InitStruct.Pin = Charge_Pin|Forward_Motor_Pin|Backward_Motor_Pin|Buzzer_Pin
                          |Operator_Light_Pin|Error_Light_Pin|Batt_lvl_1_Pin|Batt_lvl_2_Pin
                          |Batt_lvl_3_Pin|Batt_lvl_4_Pin|Batt_lvl_5_Pin|Option_Pin;
  GPIO_InitStruct.Mode = GPIO_MODE_OUTPUT_PP;
  GPIO_InitStruct.Speed = GPIO_SPEED_FREQ_HIGH;
  HAL_GPIO_Init(GPIOB, &GPIO_InitStruct);

  /*Configure GPIO pins : Forward_LMS_Pin Backward_LMS_Pin Charge_LMS_Pin */
  GPIO_InitStruct.Pin = Forward_LMS_Pin|Backward_LMS_Pin|Charge_LMS_Pin;
  GPIO_InitStruct.Mode = GPIO_MODE_INPUT;
  GPIO_InitStruct.Pull = GPIO_NOPULL;
  HAL_GPIO_Init(GPIOB, &GPIO_InitStruct);

  /*Configure GPIO pin : Charge_Finish_Pin */
  GPIO_InitStruct.Pin = Charge_Finish_Pin;
  GPIO_InitStruct.Mode = GPIO_MODE_INPUT;
  GPIO_InitStruct.Pull = GPIO_NOPULL;
  HAL_GPIO_Init(Charge_Finish_GPIO_Port, &GPIO_InitStruct);

}

void _Error_Handler(char * file, int line)
{
  while(1)
  {
  }
}

/************************ (C) COPYRIGHT STMicroelectronics *****END OF FILE****/
